# STM32WBA55 register map
File version: 1.0
CPU: CM33 r0p1, little endian, MPU, FPU, 4 interrupt priority bits
Registers are 32-bit, read-write, reset 0x0 unless marked. A register's access mark holds for its fields unless they carry their own. Offsets are from the block's base; [hi:lo] are bit positions; {n}, {i} and the like mark numbered series.

## GTZC1_TZSC
Base 0x40032400
Same registers: SEC_GTZC1_TZSC 0x50032400
0x00 CR — GTZC1 TZSC control register
  [0] LCK — lock the configuration of GTZC1_TZSC_SECCFGRn and GTZC1_TZSC_PRIVCFGRn registers until next reset This bit is cleared by default and once set, it can not be reset until system reset.
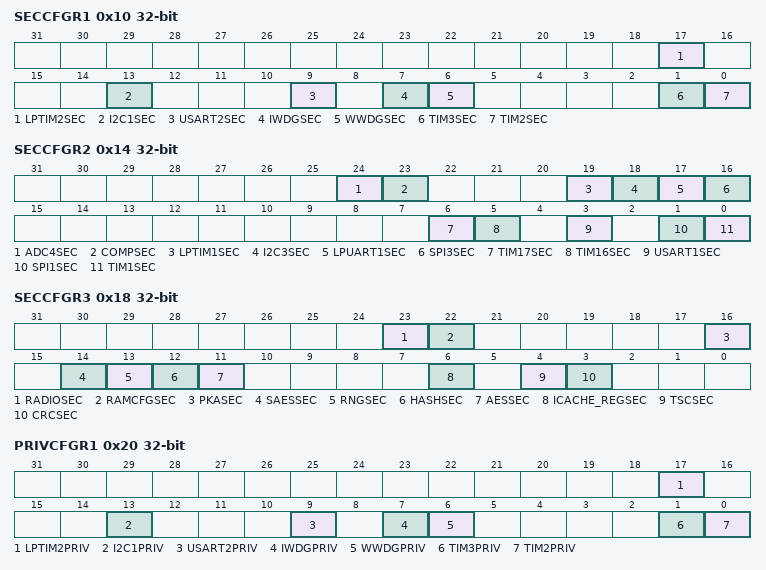
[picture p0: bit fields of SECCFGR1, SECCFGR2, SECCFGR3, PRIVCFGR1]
0x10 SECCFGR1 — GTZC1 TZSC secure configuration register 1
  [17] LPTIM2SEC — secure access mode for LPTIM2
  [13] I2C1SEC — secure access mode for I2C1
  [9] USART2SEC — secure access mode for USART2
  [7] IWDGSEC — secure access mode for IWDG
  [6] WWDGSEC — secure access mode for WWDG
  [1] TIM3SEC — secure access mode for TIM3
  [0] TIM2SEC — secure access mode for TIM2
0x14 SECCFGR2 — GTZC1 TZSC secure configuration register 2
  [24] ADC4SEC — secure access mode for ADC4
  [23] COMPSEC — secure access mode for COMP Note that bit 23 is reserved on sales type STM32WBA52.
  [19] LPTIM1SEC — secure access mode for LPTIM1
  [18] I2C3SEC — secure access mode for I2C3
  [17] LPUART1SEC — secure access mode for LPUART1
  [16] SPI3SEC — secure access mode for SPI3
  [6] TIM17SEC — secure access mode for TIM17
  [5] TIM16SEC — secure access mode for TIM16
  [3] USART1SEC — secure access mode for USART1
  [1] SPI1SEC — secure access mode for SPI1
  [0] TIM1SEC — secure access mode for TIM1
0x18 SECCFGR3 — GTZC1 TZSC secure configuration register 3
  [23] RADIOSEC — secure access mode for 2.4 GHz RADIO
  [22] RAMCFGSEC — secure access mode for RAMCFG
  [16] PKASEC — secure access mode for PKA
  [14] SAESSEC — secure access mode for SAES
  [13] RNGSEC — secure access mode for RNG
  [12] HASHSEC — secure access mode for HASH
  [11] AESSEC — secure access mode for AES
  [6] ICACHE_REGSEC — secure access mode for ICACHE registers
  [4] TSCSEC — secure access mode for TSC
  [3] CRCSEC — secure access mode for CRC
0x20 PRIVCFGR1 — GTZC1 TZSC privilege configuration register 1
  [17] LPTIM2PRIV — privileged access mode for LPTIM2
  [13] I2C1PRIV — privileged access mode for I2C1
  [9] USART2PRIV — privileged access mode for USART2
  [7] IWDGPRIV — privileged access mode for IWDG
  [6] WWDGPRIV — privileged access mode for WWDG
  [1] TIM3PRIV — privileged access mode for TIM3
  [0] TIM2PRIV — privileged access mode for TIM2
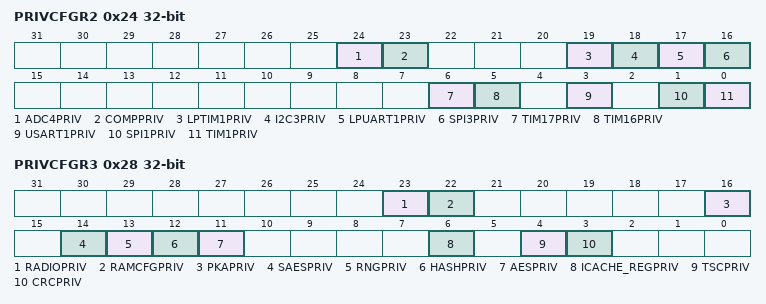
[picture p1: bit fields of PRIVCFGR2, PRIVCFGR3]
0x24 PRIVCFGR2 — GTZC1 TZSC privilege configuration register 2
  [24] ADC4PRIV — privileged access mode for ADC4
  [23] COMPPRIV — privileged access mode for COMP Note that bit 23 is reserved on sales type STM32WBA52.
  [19] LPTIM1PRIV — privileged access mode for LPTIM1
  [18] I2C3PRIV — privileged access mode for I2C3
  [17] LPUART1PRIV — privileged access mode for LPUART1
  [16] SPI3PRIV — privileged access mode for SPI3
  [6] TIM17PRIV — privileged access mode for TIM17
  [5] TIM16PRIV — privileged access mode for TIM16
  [3] USART1PRIV — privileged access mode for USART1
  [1] SPI1PRIV — privileged access mode for SPI1PRIV
  [0] TIM1PRIV — privileged access mode for TIM1
0x28 PRIVCFGR3 — GTZC1 TZSC privilege configuration register 3
  [23] RADIOPRIV — privileged access mode for 2.4 GHz RADIO
  [22] RAMCFGPRIV — privileged access mode for RAMCFG
  [16] PKAPRIV — privileged access mode for PKA
  [14] SAESPRIV — privileged access mode for SAES
  [13] RNGPRIV — privileged access mode for RNG
  [12] HASHPRIV — privileged access mode for HASH
  [11] AESPRIV — privileged access mode for AES
  [6] ICACHE_REGPRIV — privileged access mode for ICACHE registers
  [4] TSCPRIV — privileged access mode for TSC
  [3] CRCPRIV — privileged access mode for CRC

## GTZC1_MPCBB1 — GTZC1_MPCBB1 address block description
Base 0x40032C00
Same registers: GTZC1_MPCBB2 0x40033000, SEC_GTZC1_MPCBB1 0x50032C00, SEC_GTZC1_MPCBB2 0x50033000
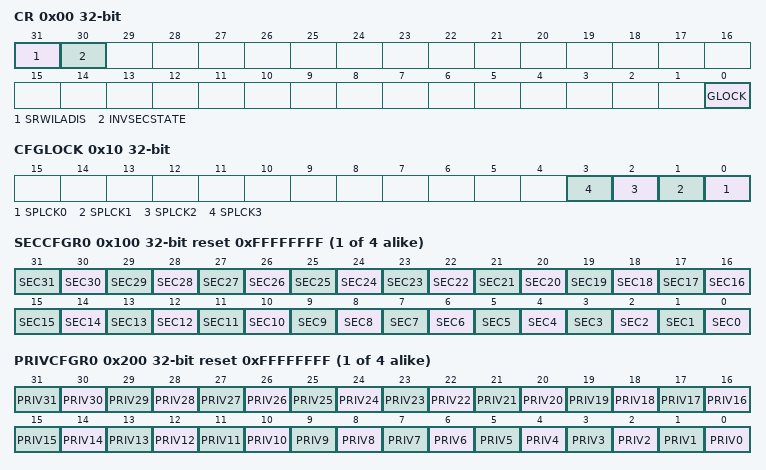
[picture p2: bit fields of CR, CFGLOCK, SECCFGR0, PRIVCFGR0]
0x00 CR — MPCBB control register
  [31] SRWILADIS — secure read/write illegal access disable; This bit disables the detection of an illegal access when a secure read/write transaction access a non-secure blocks of the block-based SRAM (secure fetch on non-secure block is always considered illegal).
  [30] INVSECSTATE — SRAM clocks security state; This bit is used to define the internal SRAM clocks control in RCC as secure or not.
  [0] GLOCK — lock the control register of the MPCBB until next reset; This bit is cleared by default and once set, it can not be reset until system reset.
0x10 CFGLOCK — GTZC1 SRAMz MPCBB configuration lock register
  [n] SPLCK{n} (n=0..3) — Security/privilege configuration lock super-block; This bit is set by software and can be cleared only by system reset.; note that bit [3:2] are reserved on sales type STM32WBA5xEx for MPCBB1.
{0x100+4i} SECCFGR{i} (i=0..3) reset 0xFFFFFFFF — MPCBBz security configuration for super-block {i} register
  [n] SEC{n} (n=0..31) — Security configuration for block y (y = 0 to 31) in super block n Unprivileged write to this bit is ignored if PRIVy bit is set in GTZC1_MPCBB_PRIVCFGRn. Writes are ignored if SPLCKn bit is set in GTZC1_MPCBB_CFGLOCK.
{0x200+4i} PRIVCFGR{i} (i=0..3) reset 0xFFFFFFFF — MPCBBz privileged configuration for super-block {i} register
  [n] PRIV{n} (n=0..31) — Privileged configuration for block y (y = 0 to 31), belonging to super-block n. Non-secure write to this bit is ignored if SECy bit is set in GTZC1_MPCBB_SECCFGRn. Writes are ignored if SPLCKn bit is set in GTZC1_MPCBB_CFGLOCK.
